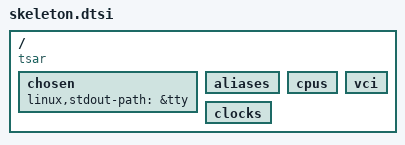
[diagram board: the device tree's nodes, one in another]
/*
 * Skeleton DTS file for TSAR
 */

/*
 * This file is mainly for fixing sections in the right order
 */

/ {
	compatible = "tsar";
	#address-cells = <2>;
	#size-cells = <2>;

	chosen {
		/* default peripheral to use when configuring earlyprintk */
		/* node: it implies that a 'tty' node must be defined */
		linux,stdout-path = &tty;
	};

	aliases { };

	cpus { };

	vci { };

	clocks { };
};
